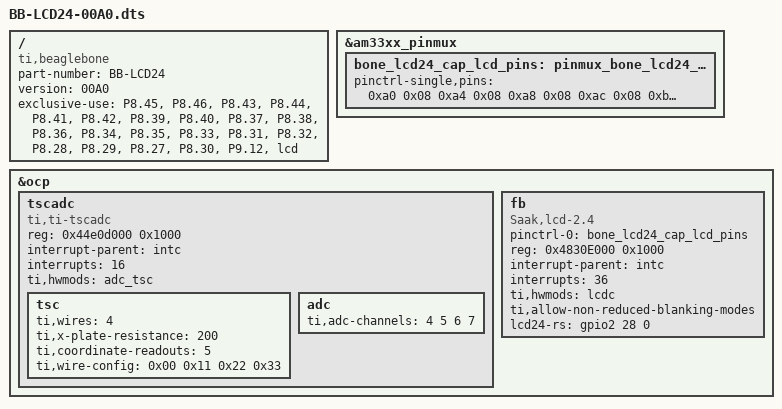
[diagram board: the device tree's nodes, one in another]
/*
* Copyright (C) 2012 Texas Instruments Incorporated - http://www.ti.com/
*
* This program is free software; you can redistribute it and/or modify
* it under the terms of the GNU General Purpose License Version 2 as
* published by the Free Software Foundation
*
* by Saak Dertadian (s.dertadian@gmail.com)
*
* Cape LCD 2.4' for Beaglebone
* usind Color LCD 240x320 (Newhaven: NHD‐2.4‐240320SF)
*
*/

/dts-v1/;
/plugin/;

/{
	compatible = "ti,beaglebone", "ti,beaglebone-black";
	part-number = "BB-LCD24";
	version = "00A0";

	/* state the resources this cape uses */
	exclusive-use =
		/* the pin header uses */
		"P8.45",	/* lcd: lcd_data0 */
		"P8.46",	/* lcd: lcd_data1 */
		"P8.43",	/* lcd: lcd_data2 */
		"P8.44",	/* lcd: lcd_data3 */
		"P8.41",	/* lcd: lcd_data4 */
		"P8.42",	/* lcd: lcd_data5 */
		"P8.39",	/* lcd: lcd_data6 */
		"P8.40",	/* lcd: lcd_data7 */
		"P8.37",	/* lcd: lcd_data8 */
		"P8.38",	/* lcd: lcd_data9 */
		"P8.36",	/* lcd: lcd_data10 */
		"P8.34",	/* lcd: lcd_data11 */
		"P8.35",	/* lcd: lcd_data12 */
		"P8.33",	/* lcd: lcd_data13 */
		"P8.31",	/* lcd: lcd_data14 */
		"P8.32",	/* lcd: lcd_data15 */
		"P8.28",	/* lcd: lcd_pclk		- RD */
		"P8.29",	/* lcd: lcd_hsync		- WR */
		"P8.27",	/* lcd: lcd_vsync		- DC */
		"P8.30",	/* lcd: lcd_ac_bias_en	- CS*/
		"P9.12",	/* Reset */
		"lcd";

	fragment@0
	{
		target = <&am33xx_pinmux>;

		__overlay__
		{
			bone_lcd24_cap_lcd_pins: pinmux_bone_lcd24_cap_lcd_pins
			{
				pinctrl-single,pins = <

					0xa0 0x08	/* lcd_data0.lcd_data0, OMAP_MUX_MODE0 | AM33XX_PIN_OUTPUT | AM33XX_PULL_DISA */
					0xa4 0x08	/* lcd_data1.lcd_data1, OMAP_MUX_MODE0 | AM33XX_PIN_OUTPUT | AM33XX_PULL_DISA */
					0xa8 0x08	/* lcd_data2.lcd_data2, OMAP_MUX_MODE0 | AM33XX_PIN_OUTPUT | AM33XX_PULL_DISA */
					0xac 0x08	/* lcd_data3.lcd_data3, OMAP_MUX_MODE0 | AM33XX_PIN_OUTPUT | AM33XX_PULL_DISA */
					0xb0 0x08	/* lcd_data4.lcd_data4, OMAP_MUX_MODE0 | AM33XX_PIN_OUTPUT | AM33XX_PULL_DISA */
					0xb4 0x08	/* lcd_data5.lcd_data5, OMAP_MUX_MODE0 | AM33XX_PIN_OUTPUT | AM33XX_PULL_DISA */
					0xb8 0x08	/* lcd_data6.lcd_data6, OMAP_MUX_MODE0 | AM33XX_PIN_OUTPUT | AM33XX_PULL_DISA */
					0xbc 0x08	/* lcd_data7.lcd_data7, OMAP_MUX_MODE0 | AM33XX_PIN_OUTPUT | AM33XX_PULL_DISA */
					0xc0 0x08	/* lcd_data8.lcd_data8, OMAP_MUX_MODE0 | AM33XX_PIN_OUTPUT | AM33XX_PULL_DISA */
					0xc4 0x08	/* lcd_data9.lcd_data9, OMAP_MUX_MODE0 | AM33XX_PIN_OUTPUT | AM33XX_PULL_DISA */
					0xc8 0x08	/* lcd_data10.lcd_data10, OMAP_MUX_MODE0 | AM33XX_PIN_OUTPUT | AM33XX_PULL_DISA */
					0xcc 0x08	/* lcd_data11.lcd_data11, OMAP_MUX_MODE0 | AM33XX_PIN_OUTPUT | AM33XX_PULL_DISA */
					0xd0 0x08	/* lcd_data12.lcd_data12, OMAP_MUX_MODE0 | AM33XX_PIN_OUTPUT | AM33XX_PULL_DISA */
					0xd4 0x08	/* lcd_data13.lcd_data13, OMAP_MUX_MODE0 | AM33XX_PIN_OUTPUT | AM33XX_PULL_DISA */
					0xd8 0x08	/* lcd_data14.lcd_data14, OMAP_MUX_MODE0 | AM33XX_PIN_OUTPUT | AM33XX_PULL_DISA */
					0xdc 0x08	/* lcd_data15.lcd_data15, OMAP_MUX_MODE0 | AM33XX_PIN_OUTPUT | AM33XX_PULL_DISA */
					0xe8 0x00	/* lcd_pclk.lcd_pclk/rd, OMAP_MUX_MODE0 | AM33XX_PIN_OUTPUT */
					0xe4 0x00	/* lcd_hsync.lcd_hsync/wr, OMAP_MUX_MODE0 | AM33XX_PIN_OUTPUT */
					0xe0 0x00	/* lcd_vsync.lcd_vsync/dc, OMAP_MUX_MODE0 | AM33XX_PIN_OUTPUT */
					0xec 0x00	/* lcd_ac_bias_en.lcd_ac_bias_en/cs, OMAP_MUX_MODE0 | AM33XX_PIN_OUTPUT */
					0x78 0x7F	/* P9_12  60  OUTPUT MODE7 - RS  GPIO1_28 */
				>;
			};
		};
	};

	fragment@1
	{
		target = <&ocp>;
		__overlay__
		{
			#address-cells = <1>;
			#size-cells = <1>;

			tscadc
			{
				compatible = "ti,ti-tscadc";
				reg = <0x44e0d000 0x1000>;

				interrupt-parent = <&intc>;
				interrupts = <16>;
				ti,hwmods = "adc_tsc";
				status = "okay";

				tsc {
					ti,wires = <4>;
					ti,x-plate-resistance = <200>;
					ti,coordinate-readouts = <5>;
					ti,wire-config = <0x00 0x11 0x22 0x33>;
				};

				adc {
					ti,adc-channels = <4 5 6 7>;
				};
			};

			fb
			{
				compatible = "Saak,lcd-2.4";
				pinctrl-names = "default";
				pinctrl-0 = <&bone_lcd24_cap_lcd_pins>;
				reg = <0x4830E000 0x1000>;
				interrupt-parent = <&intc>;
				interrupts = <36>;
				ti,hwmods = "lcdc";
				ti,allow-non-reduced-blanking-modes;
				lcd24-rs = <&gpio2 28 0>;
			};
		};
	};
};
